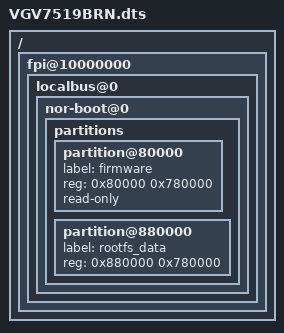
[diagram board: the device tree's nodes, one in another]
/dts-v1/;


/include/ "VGV7519.dtsi"

/ {
	fpi@10000000 {
		localbus@0 {
			nor-boot@0 {
				partitions {
					partition@80000 {
						label = "firmware";
						reg = <0x80000 0x780000>;
						read-only;
					};
					partition@880000 {
						label = "rootfs_data";
						reg = <0x880000 0x780000>;
					};
				};
			};
		};
	};
};
